# ESP32-P4 register map
Vendor: ESPRESSIF SYSTEMS (SHANGHAI) CO., LTD.; Series: ESP32 P-Series; File version: 3
CPU: RV32IMAFC r0p0, little endian, no MPU, FPU, 0 interrupt priority bits
Address unit: 32 bits
Registers are 32-bit, read-write, reset 0x0 unless marked. A register's access mark holds for its fields unless they carry their own. Offsets are from the block's base; [hi:lo] are bit positions.

## I3C_SLV — I3C Controller (Slave)
Base 0x500DB000
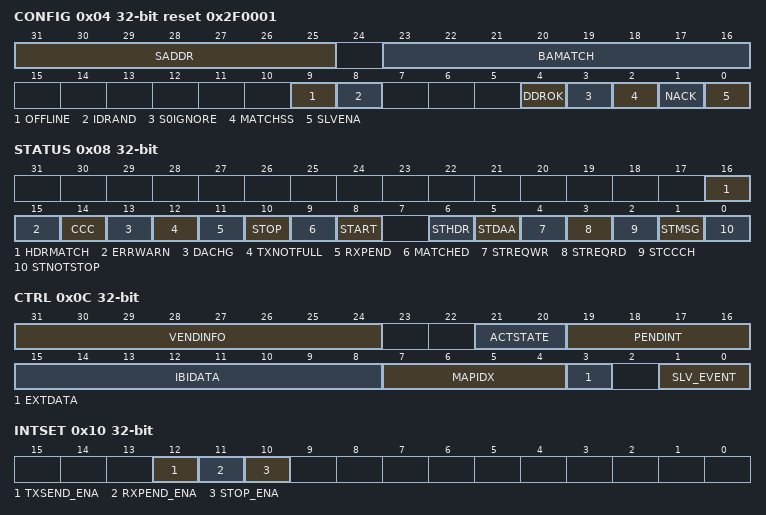
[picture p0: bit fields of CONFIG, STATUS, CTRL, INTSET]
0x04 CONFIG reset 0x2F0001
  [31:25] SADDR — If allowed by the block:sets i2c 7 bits static address,else should be 0. If enabled to use one and to be provided by SW. Block may provide in HW as well.
  [23:16] BAMATCH — Bus Available condition match value for current ???Slow clock???. This provides the count of the slow clock to count out 1us (or more) to allow an IBI to drive SDA Low when the Master is not doing so. The max width , and so max value, is controlled by the block. Only if enabled for events such IBI or MR or HJ, and if enabled to provide this as a register. With is limited to CLK_SLOW_BITS
  [9] OFFLINE
  [8] IDRAND
  [4] DDROK
  [3] S0IGNORE — If 1, the Slave will not detect S0 or S1 errors and so not lock up waiting on an Exit Pattern. This should only be used when the bus will not use HDR.
  [2] MATCHSS — 1: the START and STOP sticky STATUS bits will only be set if MATCHED is set..This allows START and STOP to be used to detect end of a message to /from this slave.
  [1] NACK — 1:the slave will NACK all requests to it except CCC broadcast. This should be used with caution as the Master may determine the slave is missing if overused.
  [0] SLVENA — 1: allow the slave to operate on i2c or i3c bus. 0: the slave will ignore the bus. This should be not set until registers such as PARTNO, IDEXT and the like are set 1st -if used- since they impact data to the master
0x08 STATUS access per field
  [16] HDRMATCH rw
  [15] ERRWARN ro
  [14] CCC rw — A common -command-code(CCC), not handled by block, has been received. This acts differently between: *Broadcasted ones, which will then also correspond with RXPEND and the 1st byte will be the CCC(command) . *Direct ones, which may never be directed to this device. If it is, then the TXSEND or RXPEND will be triggered with this end the RXPEND will contain the command.
  [13] DACHG rw — The Slv Dynamic Address has been assigned, reassigned, or reset(lost) and is now in that state of being valid or none. Actual DA can be seen in the DYNADDR register. Note that this will also be used when MAP Auto feature is configured. This will be changing one or more MAP items. See DYNADDR and/or MAPCTRLn. DYNAADDR for the main DA(0) will indicate if last change was due to Auto MAP.
  [12] TXNOTFULL ro — Is 1 when the To-bus buffer/FIFO can accept more data to go out. Defau:1. For all but External FIFO, this uses DATACTRL TXTRIG,which defaults to not-full. If DMA is enabled for TX, it will also be signaled to provide more.
  [11] RXPEND ro — Receiving a message from master,which is not being handled by block(not a CCC internally processed). For all but External FIFO, this uses DATACTRL RXTRIG, which defaults to not-empty. If DMA is enabled for RX, DMA will be signaled as well. Will self-clear if data is read(FIFO and non-FIFO)
  [10] STOP rw
  [9] MATCHED rw
  [8] START rw
  [6] STHDR ro
  [5] STDAA ro
  [4] STREQWR ro
  [3] STREQRD ro — 1 if the req in process is an sdr read from this slave or an IBI is being pushed out,
  [2] STCCCH ro — Is 1 if a CCC message is being handled automatically.
  [1] STMSG ro — Is 1 if this bus Slave is listening to the bus traffic or repsonding, If STNOSTOP=1, then this will be 0 when a non-matching address seen until next respeated START it STOP.
  [0] STNOTSTOP ro — Is 1 if bus is busy(activity) and 0 when in a STOP condition. Other bits may also set when busy. Note that this can also be true from an S0 or S1 error, which waits for an Exit Pattern.
0x0C CTRL
  [31:24] VENDINFO
  [21:20] ACTSTATE
  [19:16] PENDINT — Should be set to the pending interrupt that GETSTATUS CCC will return. This should be maintained by the application if used and configured, as the Master will read this. If not configured, the GETSTATUS field will return 1 if an IBI is pending, and 0 otherwise.
  [15:8] IBIDATA — Data byte to go with an IBI, if enabled for it. If enabled (was in BCR), then it is required.
  [7:4] MAPIDX — Index of Dynamic Address that IBI is for. This is 0 for the main or base Dynamic Address, or can be any valid index.
  [3] EXTDATA — reserved
  [1:0] SLV_EVENT — If set to non-0, will request an event. Once requested, STATUS.EVENT and EVDET will show the status as it progresses. Once completed, the field will automatically return to 0. Once non-0, only 0 can be written(to cancel) until done. 0: Normal mode. If set to 0 after was a non-0 value, will cancel if not already in flight. 1: start an IBI. This will try to push through an IBI on the bus. If data associate with the IBI, it will be drawn from the IBIDATA field. Note that if Time control is enabled, this will include anytime control related bytes further, the IBIDATA byte will have bit7 set to 1.
0x10 INTSET — INSET allows setting enables for interrupts(connecting the corresponding STATUS source to causing an IRQ to the processor)
  [12] TXSEND_ENA
  [11] RXPEND_ENA — Interrupt when receiving a message from Master, which is not being handled by the block (excludes CCCs being handled automatically). If FIFO, then RX fullness trigger. If DMA, then message end.
  [10] STOP_ENA — Interrupt on STOP state on the bus. See Start as the preferred interrupt when needed. This interrupt may not trigger for quick STOP/START combination, as it relates to the state of being stopped.
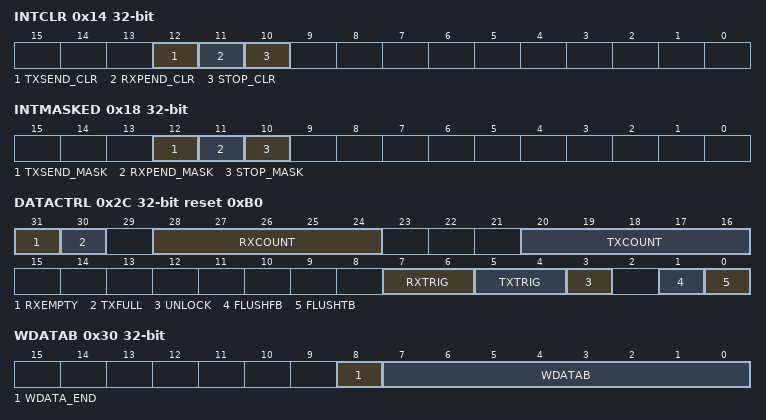
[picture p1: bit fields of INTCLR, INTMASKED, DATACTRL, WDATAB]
0x14 INTCLR wo
  [12] TXSEND_CLR
  [11] RXPEND_CLR — Interrupt when receiving a message from Master, which is not being handled by the block (excludes CCCs being handled automatically). If FIFO, then RX fullness trigger. If DMA, then message end.
  [10] STOP_CLR — Interrupt on STOP state on the bus. See Start as the preferred interrupt when needed. This interrupt may not trigger for quick STOP/START combination, as it relates to the state of being stopped.
0x18 INTMASKED ro
  [12] TXSEND_MASK
  [11] RXPEND_MASK — Interrupt when receiving a message from Master, which is not being handled by the block (excludes CCCs being handled automatically). If FIFO, then RX fullness trigger. If DMA, then message end.
  [10] STOP_MASK — Interrupt on STOP state on the bus. See Start as the preferred interrupt when needed. This interrupt may not trigger for quick STOP/START combination, as it relates to the state of being stopped.
0x2C DATACTRL access per field reset 0xB0
  [31] RXEMPTY ro
  [30] TXFULL ro
  [28:24] RXCOUNT ro
  [20:16] TXCOUNT ro
  [7:6] RXTRIG rw — Trigger level for rx fulless when FIFOed, Affects interrupt and DMA(if enabled). The defaults is 3
  [5:4] TXTRIG rw — Trigger level for tx emptiness when FIFOed, Affects interrupt and DMA(if enabled). The defaults is 3
  [3] UNLOCK wo — If this bit is not written 1, the register bits from 7 to 4 are not changed on write.
  [1] FLUSHFB wo — Flushes the to-bus buffer/FIFO. Used when Master terminates a to-bus (read) message prematurely
  [0] FLUSHTB wo — Flushes the from-bus buffer/FIFO. Not normally used
0x30 WDATAB wo
  [8] WDATA_END, [7:0] WDATAB
0x34 WDATABE wo
  [7:0] WDATABE
0x40 RDARAB ro — Read Byte Data (from-bus) register
  [7:0] DATA0 — This register allows reading a byte from the bus unless external FIFO is used. A byte should not be read unless there is data waiting, as indicated by the RXPEND bit being set in the STATUS register
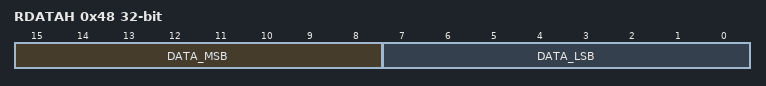
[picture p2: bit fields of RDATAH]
0x48 RDATAH ro — Read Half-word Data (from-bus) register
  [15:8] DATA_MSB — This register allows reading a Half-word (byte pair) from the bus unless external FIFO is used. A Half-word should not be read unless there is at least 2 bytes of data waiting, as indicated by the RX FIFO level trigger or RXCOUNT available space in the DATACTRL register
  [7:0] DATA_LSB
0x5C CAPABILITIES2 ro reset 0x100
  [31:0] CAPABLITIES2
0x60 CAPABILITIES ro reset 0x7C13FC1C
  [31:0] CAPABLITIES
0x6C IDPARTNO
  [31:0] PARTNO
0x70 IDEXT
0x74 VENDORID reset 0x5550
  [14:0] VID
